# STM32C562xx register map
File version: 1.0
Registers are 32-bit, read-write, reset 0x0 unless marked. A register's access mark holds for its fields unless they carry their own. Offsets are from the block's base; [hi:lo] are bit positions; {n}, {i} and the like mark numbered series; 'fields as' and 'values as' point back to an identical list.

## USB_DRD_PMA_BUFF — Universal Serial Bus PacketMemoryArea Buffer Descriptor Table
Base 0x40016400
0x00 TXBD — Transmission buffer address
0x04 RXBD — Reception buffer address

## LPDMA1 — DMA Controller (DMA)
Base 0x40020000
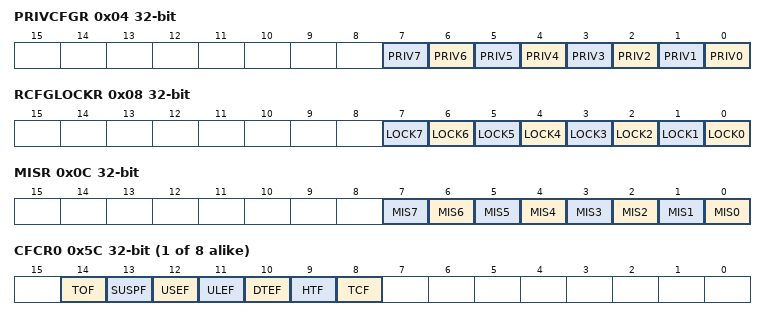
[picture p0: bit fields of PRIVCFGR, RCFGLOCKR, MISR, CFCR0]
0x04 PRIVCFGR — DMA privileged configuration register
  [n] PRIV{n} (n=0..7)
0x08 RCFGLOCKR — DMA configuration lock register
  [n] LOCK{n} (n=0..7)
0x0C MISR ro — DMA masked interrupt status register
  [n] MIS{n} (n=0..7)
{0x50+0x80*i} CLBAR{i} (i=0..7) — DMA channel x linked-list base address register
  [31:16] LBA
{0x5C+0x80*i} CFCR{i} (i=0..7) — DMA channel x flag clear register
  [14] TOF, [13] SUSPF, [12] USEF, [11] ULEF, [10] DTEF, [9] HTF, [8] TCF
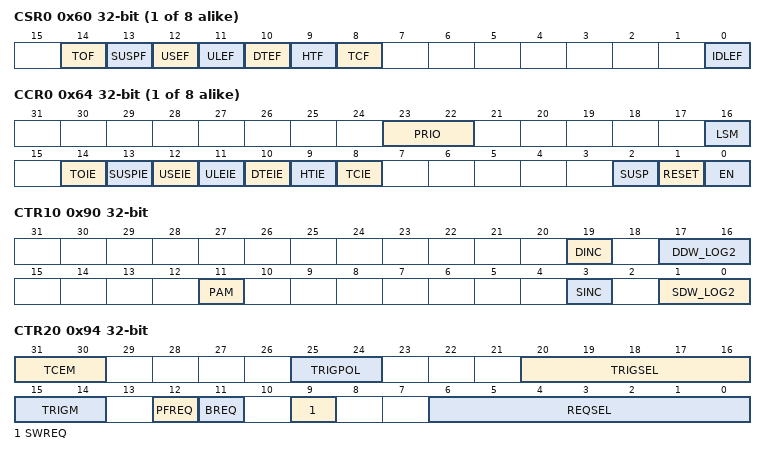
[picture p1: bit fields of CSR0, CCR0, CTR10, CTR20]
{0x60+0x80*i} CSR{i} ro (i=0..7) — DMA channel x flag status register
  [14] TOF — Trigger overrun flag
  [13] SUSPF — Completed suspension flag
  [12] USEF — User setting error flag
  [11] ULEF
  [10] DTEF — Data transfer error flag
  [9] HTF — Half transfer complete flag
  [8] TCF — Transfer complete flag
  [0] IDLEF — Idle flag
{0x64+0x80*i} CCR{i} (i=0..7) — DMA channel x control register
  [23:22] PRIO — Priority level
  [16] LSM — Link step mode
  [14] TOIE
  [13] SUSPIE
  [12] USEIE
  [11] ULEIE
  [10] DTEIE
  [9] HTIE
  [8] TCIE
  [2] SUSP — Channel suspend
  [1] RESET — Channel reset
  [0] EN — Channel enable
0x90 CTR10 — DMA channel x transfer register 1
  [19] DINC
  [17:16] DDW_LOG2
  [11] PAM — Padding / alignment mode
  [3] SINC — Source incrementing burst
  [1:0] SDW_LOG2
0x94 CTR20 — DMA channel x transfer register 2
  [31:30] TCEM
  [25:24] TRIGPOL
  [20:16] TRIGSEL
  [15:14] TRIGM — Trigger mode
  [12] PFREQ
  [11] BREQ — Block hardware request
  [9] SWREQ — Software request
  [6:0] REQSEL
0x98 CBR10 — DMA channel x block register 1
  [15:0] BNDT
{0x9C+0x80*i} CSAR{i} (i=0..7) — DMA channel x source address register
  [31:0] SA — Source Address
{0xA0+0x80*i} CDAR{i} (i=0..7) — DMA channel x destination address register
  [31:0] DA — Destination address
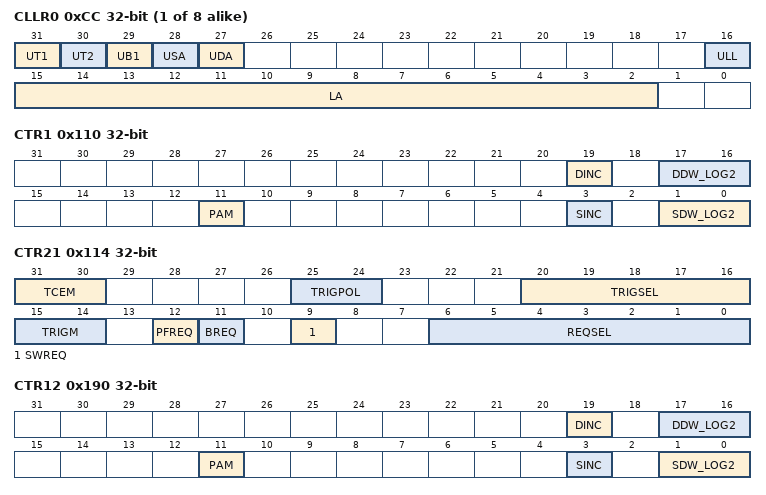
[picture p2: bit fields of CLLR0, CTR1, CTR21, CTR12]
{0xCC+0x80*i} CLLR{i} (i=0..7) — DMA channel x linked-list address register
  [31] UT1, [30] UT2, [29] UB1, [28] USA, [27] UDA, [16] ULL, [15:2] LA
0x110 CTR1 — DMA channel x transfer register 1
  fields as CTR10
0x114 CTR21 — DMA channel x transfer register 2
  fields as CTR20
0x118 CBR1 — DMA channel x block register 1
  [15:0] BNDT
0x190 CTR12 — DMA channel x transfer register 1
  fields as CTR10
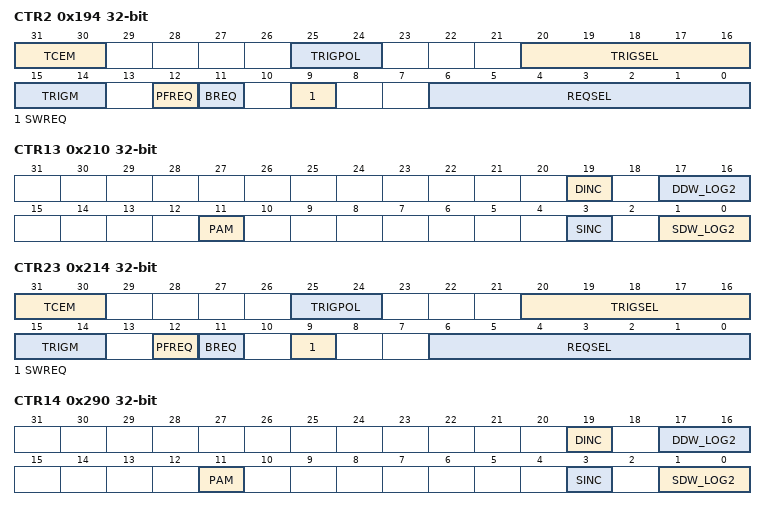
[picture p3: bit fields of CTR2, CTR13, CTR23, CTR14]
0x194 CTR2 — DMA channel x transfer register 2
  fields as CTR20
0x198 CBR12 — DMA channel x block register 1
  [15:0] BNDT
0x210 CTR13 — DMA channel x transfer register 1
  fields as CTR10
0x214 CTR23 — DMA channel x transfer register 2
  fields as CTR20
0x218 CBR13 — DMA channel x block register 1
  [15:0] BNDT
0x290 CTR14 — DMA channel x transfer register 1
  fields as CTR10
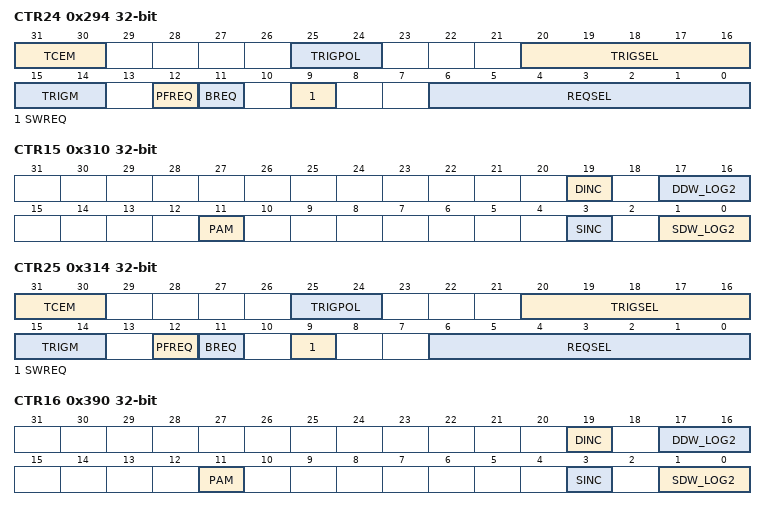
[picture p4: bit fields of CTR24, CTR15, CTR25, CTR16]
0x294 CTR24 — DMA channel x transfer register 2
  fields as CTR20
0x298 CBR14 — DMA channel x block register 1
  [15:0] BNDT
0x310 CTR15 — DMA channel x transfer register 1
  fields as CTR10
0x314 CTR25 — DMA channel x transfer register 2
  fields as CTR20
0x318 CBR15 — DMA channel x block register 1
  [15:0] BNDT
0x390 CTR16 — DMA channel x transfer register 1
  fields as CTR10
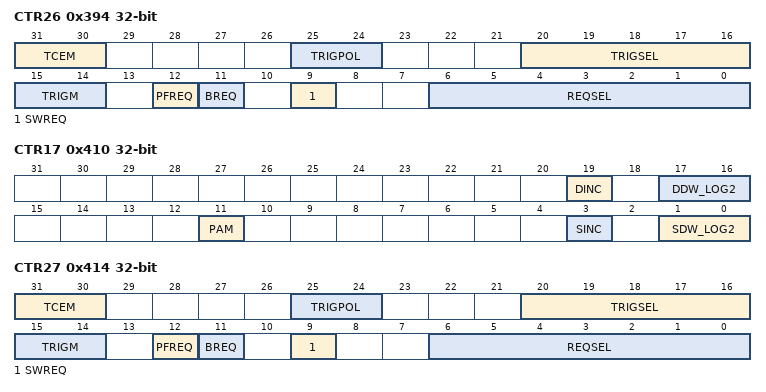
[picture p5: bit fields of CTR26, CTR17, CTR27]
0x394 CTR26 — DMA channel x transfer register 2
  fields as CTR20
0x398 CBR16 — DMA channel x block register 1
  [15:0] BNDT
0x410 CTR17 — DMA channel x transfer register 1
  fields as CTR10
0x414 CTR27 — DMA channel x transfer register 2
  fields as CTR20
0x418 CBR17 — DMA channel x block register 1
  [15:0] BNDT

## LPDMA2 — DMA Controller (DMA)
Base 0x40021000
Registers as LPDMA1, without CLBAR{n} (n=4..7), CFCR{n} (n=4..7), CSR{n} (n=4..7), CCR{n} (n=4..7), CTR{n} (n=14..17), CTR{n} (n=24..27), CBR{n} (n=14..17), CSAR{n} (n=4..7), CDAR{n} (n=4..7), CLLR{n} (n=4..7).
